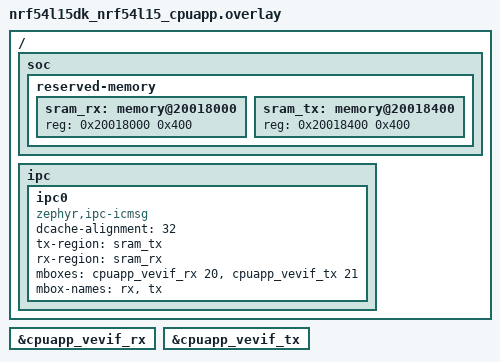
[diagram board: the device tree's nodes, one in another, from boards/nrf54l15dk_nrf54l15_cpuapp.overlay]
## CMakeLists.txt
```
#
# Copyright (c) 2025, Jamie M.
#
# All right reserved. This code is NOT apache or FOSS/copyleft licensed.
#

cmake_minimum_required(VERSION 3.20.0)

find_package(Zephyr REQUIRED HINTS $ENV{ZEPHYR_BASE})
project(test_app_main)

target_sources(app PRIVATE src/main.c src/ipc_endpoint.c src/flipper_cpu.c src/ipc_settings.c src/ipc_crypto.c)

zephyr_include_directories(${ZEPHYR_BINARY_DIR}/include)
generate_inc_file_for_target(
  app
  ${ZEPHYR_BINARY_DIR}/../../remote/zephyr/zephyr.bin
  ${ZEPHYR_BINARY_DIR}/include/generated/remote.inc
  )

zephyr_linker_sources(ROM_START flipper_code.ld)
```

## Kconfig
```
#
# Copyright (c) 2025, Jamie M.
#
# All right reserved. This code is NOT apache or FOSS/copyleft licensed.
#

config IPC_SETTINGS_SERVER
	bool "IPC settings server"
	imply ZMS
	imply ZMS_LOOKUP_CACHE
	imply ZMS_DATA_CRC
	imply ZMS_NO_DOUBLE_WRITE
	select SETTINGS
	imply SETTINGS_RUNTIME
	imply SETTINGS_ZMS_LL_CACHE
	select FLASH
	select FLASH_MAP

config IPC_SETTINGS_CLIENT
	bool "IPC settings client"
	select SETTINGS
	imply SETTINGS_RUNTIME

config IPC_LORAWAN_CRYPTO_SERVER
	bool "IPC LoRaWAN crypto server"

if IPC_SETTINGS_CLIENT

choice SETTINGS_BACKEND
        prompt "Storage back-end"
        default SETTINGS_IPC

config SETTINGS_IPC
        bool "IPC"
        help
          Use IPC as settings storage backend.

endchoice

endif # IPC_SETTINGS_CLIENT

if LORAWAN

choice LORAWAN_NVM
        prompt "LoRaWAN NVM backend"
        default LORAWAN_NVM_IPC_SETTINGS if IPC_SETTINGS_CLIENT

config LORAWAN_NVM_IPC_SETTINGS
        bool "IPC settings based NVM"
        depends on IPC_SETTINGS_CLIENT

endchoice

config IPC_LORAWAN_CRYPTO_CLIENT
	bool "IPC LoRaWAN crypto client"
	select LORAWAN_BELL_IPC_CRYPTO_CLIENT

config LORAWAN_BELL_IPC_CRYPTO_CLIENT
	bool "LoRaWAN IPC secure enclare backend"

endif # LORAWAN

source "Kconfig.zephyr"
```

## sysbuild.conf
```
SB_CONFIG_BOOTLOADER_MCUBOOT=y
SB_CONFIG_APP_USE_COMBINED_HEX_FILE=y
```

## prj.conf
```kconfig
CONFIG_PRINTK=y

CONFIG_LOG=y
CONFIG_LOG_PROCESS_THREAD_PRIORITY=-15
CONFIG_LOG_PROCESS_THREAD_CUSTOM_PRIORITY=y

CONFIG_MAIN_STACK_SIZE=4096
CONFIG_HEAP_MEM_POOL_SIZE=4096

CONFIG_MBOX=y

CONFIG_IPC_SERVICE=y
CONFIG_IPC_SERVICE_LOG_LEVEL_INF=y
CONFIG_IPC_SETTINGS_SERVER=y
CONFIG_IPC_SERVICE_BACKEND_ICMSG_WQ_STACK_SIZE=4096
CONFIG_IPC_LORAWAN_CRYPTO_SERVER=y
CONFIG_PBUF_RX_READ_BUF_SIZE=512
CONFIG_HEAP_MEM_POOL_SIZE=4096

CONFIG_NRF_SECURITY=y

CONFIG_MBEDTLS_PSA_CRYPTO_C=y
CONFIG_MBEDTLS_ENABLE_HEAP=y
CONFIG_MBEDTLS_HEAP_SIZE=8192

CONFIG_PSA_WANT_GENERATE_RANDOM=y
CONFIG_PSA_WANT_KEY_TYPE_AES=y
CONFIG_PSA_WANT_ALG_ECB_NO_PADDING=y
CONFIG_PSA_WANT_ALG_CMAC=y
CONFIG_PSA_CRYPTO_DRIVER_OBERON=n
CONFIG_PSA_CRYPTO_DRIVER_CRACEN=y
```

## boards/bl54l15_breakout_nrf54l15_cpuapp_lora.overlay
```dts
&cpuflpr_vpr {
	status = "okay";
};
```

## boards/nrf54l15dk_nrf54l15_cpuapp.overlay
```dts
/*
 * Copyright (c) 2025 Nordic Semiconductor ASA
 *
 * SPDX-License-Identifier: LicenseRef-Nordic-5-Clause
 */

/ {
	soc {
		reserved-memory {
			#address-cells = <1>;
			#size-cells = <1>;

                        sram_rx: memory@20018000 {
                                reg = <0x20018000 0x400>;
                        };

                        sram_tx: memory@20018400 {
                                reg = <0x20018400 0x400>;
                        };
		};
	};

	ipc {
		ipc0: ipc0 {
			compatible = "zephyr,ipc-icmsg";
			dcache-alignment = <32>;
			tx-region = <&sram_tx>;
			rx-region = <&sram_rx>;
			mboxes = <&cpuapp_vevif_rx 20>, <&cpuapp_vevif_tx 21>;
			mbox-names = "rx", "tx";
			status = "okay";
		};
	};
};

&cpuapp_vevif_rx {
	status = "okay";
};

&cpuapp_vevif_tx {
	status = "okay";
};
```

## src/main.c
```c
/*
 * Copyright (c) 2025, Jamie M.
 *
 * All right reserved. This code is NOT apache or FOSS/copyleft licensed.
 */

#include "ipc_endpoint.h"
#include "ipc_settings.h"
#include <zephyr/kernel.h>
#include <zephyr/settings/settings.h>
#include <zephyr/logging/log.h>

#ifdef CONFIG_IPC_LORAWAN_CRYPTO_SERVER
#include <psa/crypto.h>
#include <psa/crypto_extra.h>
#endif

LOG_MODULE_REGISTER(main, 4);

static uint8_t data[3];

int main(void)
{
	int rc;
	uint8_t up_value = 0;

#ifdef CONFIG_IPC_LORAWAN_CRYPTO_SERVER
	psa_status_t status;
#endif

LOG_ERR("aa1");
	rc = ipc_setup();

	if (rc != 0) {
		return 0;
	}

	rc = settings_subsys_init();

#ifdef CONFIG_IPC_SETTINGS_SERVER
	rc = settings_load();
#endif

LOG_ERR("aa2");
	rc = ipc_wait_for_ready();

	if (rc != 0) {
		return 0;
	}

#ifdef CONFIG_IPC_SETTINGS_SERVER
	ipc_setting_boot_load("lorawan");
#endif

#ifdef CONFIG_IPC_LORAWAN_CRYPTO_SERVER
	status = psa_crypto_init();
	if (status != PSA_SUCCESS) {
		LOG_ERR("Crypto init failed: %d", status);
	}
#endif

LOG_ERR("aa3");
	while (1) {
		k_sleep(K_MSEC(2000));

		data[0] = up_value++;
		data[1] = up_value++;
		data[2] = up_value++;

LOG_HEXDUMP_ERR(data, sizeof(data), "in");

		rc = ipc_send_message(0, sizeof(data), data);

		if (rc < 0) {
			LOG_ERR("Failed to send: %d", rc);
		}
	}

	return 0;
}
```

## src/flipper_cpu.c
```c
/*
 * Copyright (c) 2025, Jamie M.
 *
 * All right reserved. This code is NOT apache or FOSS/copyleft licensed.
 */

#include <zephyr/kernel.h>
#include <zephyr/init.h>
#include <zephyr/devicetree.h>
#include <zephyr/logging/log.h>
#include <hal/nrf_vpr.h>

#define FLPR_SECURE_MODE

#if defined(FLPR_SECURE_MODE) && !defined(CONFIG_TRUSTED_EXECUTION_NONSECURE)
#include <hal/nrf_spu.h>
#endif

static __aligned(0x800) __used __attribute__((section("._flpr_code"))) const uint8_t flpr_firmware[] = {
#include <generated/remote.inc>
};

LOG_MODULE_REGISTER(flpr_cpu, 4);

static int flipper_cpu_launch(void)
{
	NRF_VPR_Type *flpr_cpu = (NRF_VPR_Type *)DT_REG_ADDR(DT_NODELABEL(cpuflpr_vpr));

#if defined(FLPR_SECURE_MODE)
	nrf_spu_periph_perm_secattr_set(NRF_SPU00, nrf_address_slave_get((uint32_t)flpr_cpu),
					true);
#endif

	nrf_vpr_initpc_set(flpr_cpu, (uint32_t)flpr_firmware);
	nrf_vpr_cpurun_set(flpr_cpu, true);

	return 0;
}

SYS_INIT(flipper_cpu_launch, POST_KERNEL, 0);
```

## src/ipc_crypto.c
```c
/*
 * Copyright (c) 2025, Jamie M.
 *
 * All right reserved. This code is NOT apache or FOSS/copyleft licensed.
 */

#include <stdlib.h>
#include <zephyr/types.h>
#include <zephyr/kernel.h>
#include <zephyr/init.h>
#include <zephyr/logging/log.h>
#include "ipc_endpoint.h"
#include "ipc_crypto.h"

#if defined(CONFIG_IPC_LORAWAN_CRYPTO_SERVER)
#elif defined(CONFIG_IPC_LORAWAN_CRYPTO_CLIENT)
#endif

#ifdef CONFIG_IPC_LORAWAN_CRYPTO_SERVER
#include <psa/crypto.h>
#include <psa/crypto_extra.h>
#endif

#define CMAC_AES128_SIZE 16

LOG_MODULE_REGISTER(ipc_crypto, 4);

struct ipc_lorawan_crypto_set_key_data {
	uint8_t type;
	uint16_t key_size;
	uint8_t key[];
};

struct ipc_lorawan_crypto_set_key_response_data {
	int rc;
};

struct ipc_lorawan_crypto_aes128_encrypt_data {
	uint8_t key_id;
	uint16_t data_size;
	uint8_t data[];
};

struct ipc_lorawan_crypto_aes128_encrypt_response_data {
	int rc;
	uint16_t data_size;
	uint8_t data[];
};

struct ipc_lorawan_crypto_cmac_aes128_verify_data {
	uint8_t key_id;
	uint16_t data_size;
	uint16_t signature_size;
	uint8_t data[]; //Data followed by signature
};

struct ipc_lorawan_crypto_cmac_aes128_verify_response_data {
	int rc;
};

/* Client -> server */
static int ipc_lorawan_crypto_callback_set_key(const uint8_t *message, uint16_t size, void *user_data);
static int ipc_lorawan_crypto_callback_aes128_ecb_encrypt(const uint8_t *message, uint16_t size, void *user_data);
static int ipc_lorawan_crypto_callback_aes128_ccm_encrypt(const uint8_t *message, uint16_t size, void *user_data);
static int ipc_lorawan_crypto_callback_cmac_aes128_encrypt(const uint8_t *message, uint16_t size, void *user_data);
static int ipc_lorawan_crypto_callback_cmac_aes128_verify(const uint8_t *message, uint16_t size, void *user_data);

#if defined(CONFIG_IPC_LORAWAN_CRYPTO_CLIENT)
static struct {
	struct k_sem busy;
	struct k_sem done;
	int rc;
	uint8_t *load_pointer;
	uint16_t load_size;
} ipc_lorawan_crypto_data;

static struct ipc_group ipc_group_set_key = {
	.callback = ipc_lorawan_crypto_callback_set_key,
	.opcode = IPC_OPCODE_CRYPTO_SET_KEY,
	.user_data = &ipc_lorawan_crypto_data,
};

static struct ipc_group ipc_group_aes128_ecb_encrypt = {
	.callback = ipc_lorawan_crypto_callback_aes128_ecb_encrypt,
	.opcode = IPC_OPCODE_CRYPTO_AES128_ECB_ENCRYPT,
	.user_data = &ipc_lorawan_crypto_data,
};

static struct ipc_group ipc_group_aes128_ccm_encrypt = {
	.callback = ipc_lorawan_crypto_callback_aes128_ccm_encrypt,
	.opcode = IPC_OPCODE_CRYPTO_AES128_CCM_ENCRYPT,
	.user_data = &ipc_lorawan_crypto_data,
};

static struct ipc_group ipc_group_cmac_aes128_encrypt = {
	.callback = ipc_lorawan_crypto_callback_cmac_aes128_encrypt,
	.opcode = IPC_OPCODE_CRYPTO_CMAC_AES128_ENCRYPT,
	.user_data = &ipc_lorawan_crypto_data,
};

static struct ipc_group ipc_group_cmac_aes128_verify = {
	.callback = ipc_lorawan_crypto_callback_cmac_aes128_verify,
	.opcode = IPC_OPCODE_CRYPTO_CMAC_AES128_VERIFY,
	.user_data = &ipc_lorawan_crypto_data,
};
#endif

#if defined(CONFIG_IPC_LORAWAN_CRYPTO_SERVER)
static struct ipc_group ipc_group_set_key = {
	.callback = ipc_lorawan_crypto_callback_set_key,
	.opcode = IPC_OPCODE_CRYPTO_SET_KEY,
};

static struct ipc_group ipc_group_aes128_ecb_encrypt = {
	.callback = ipc_lorawan_crypto_callback_aes128_ecb_encrypt,
	.opcode = IPC_OPCODE_CRYPTO_AES128_ECB_ENCRYPT,
};

static struct ipc_group ipc_group_aes128_ccm_encrypt = {
	.callback = ipc_lorawan_crypto_callback_aes128_ccm_encrypt,
	.opcode = IPC_OPCODE_CRYPTO_AES128_CCM_ENCRYPT,
};

static struct ipc_group ipc_group_cmac_aes128_encrypt = {
	.callback = ipc_lorawan_crypto_callback_cmac_aes128_encrypt,
	.opcode = IPC_OPCODE_CRYPTO_CMAC_AES128_ENCRYPT,
};

static struct ipc_group ipc_group_cmac_aes128_verify = {
	.callback = ipc_lorawan_crypto_callback_cmac_aes128_verify,
	.opcode = IPC_OPCODE_CRYPTO_CMAC_AES128_VERIFY,
};
#endif

#if defined(CONFIG_IPC_LORAWAN_CRYPTO_SERVER)
static psa_key_id_t magic_key_id;

static int encrypt_aes128(psa_key_id_t *key_id, uint8_t mode, uint8_t *data, uint16_t data_size, uint8_t *encrypted_data)
{
	/* ECB at present */
	uint32_t output_size;
	psa_status_t status;
	psa_cipher_operation_t operation = PSA_CIPHER_OPERATION_INIT;

	status = psa_cipher_encrypt_setup(&operation, *key_id, PSA_ALG_ECB_NO_PADDING);

	if (status != PSA_SUCCESS) {
		LOG_ERR("AES128 ECB setup failed: %d", status);
		return -EINVAL;
	}

	status = psa_cipher_update(&operation, data, data_size, encrypted_data, data_size, &output_size);

	if (status != PSA_SUCCESS) {
		LOG_ERR("AES128 ECB update failed: %d", status);
		return -EINVAL;
	}

	status = psa_cipher_finish(&operation, (encrypted_data + output_size), (data_size - output_size), &output_size);

	if (status != PSA_SUCCESS) {
		LOG_ERR("AES128 ECB finish failed: %d", status);
		return -EINVAL;
	}

LOG_HEXDUMP_ERR(data, data_size, "in");
LOG_HEXDUMP_ERR(encrypted_data, data_size, "out");

	psa_cipher_abort(&operation);

	return 0;
}

static int encrypt_cmac_aes128(psa_key_id_t *key_id, uint8_t *data, uint16_t data_size, uint8_t *cmac, uint16_t cmac_size)
{
	uint32_t output_size;
	psa_status_t status;
	psa_mac_operation_t operation = PSA_MAC_OPERATION_INIT;

	status = psa_mac_sign_setup(&operation, *key_id, PSA_ALG_CMAC);

	if (status != PSA_SUCCESS) {
		LOG_ERR("CMAC AES128 setup failed: %d", status);
		return -EINVAL;
	}

	status = psa_mac_update(&operation, data, data_size);

	if (status != PSA_SUCCESS) {
		LOG_ERR("CMAC AES128 update failed: %d", status);
		return -EINVAL;
	}

	status = psa_mac_sign_finish(&operation, cmac, cmac_size, &output_size);

	if (status != PSA_SUCCESS) {
		LOG_ERR("CMAC AES128 finish failed: %d", status);
		return -EINVAL;
	}

	return 0;
}

static int verify_cmac_aes128(psa_key_id_t *key_id, uint8_t *data, uint16_t data_size, uint8_t *cmac, uint16_t cmac_size)
{
	psa_status_t status;
	psa_mac_operation_t operation = PSA_MAC_OPERATION_INIT;

	status = psa_mac_verify_setup(&operation, *key_id, PSA_ALG_CMAC);

	if (status != PSA_SUCCESS) {
		LOG_ERR("CMAC AES128 setup failed: %d", status);
		return -EINVAL;
	}

	status = psa_mac_update(&operation, data, data_size);

	if (status != PSA_SUCCESS) {
		LOG_ERR("CMAC AES128 update failed: %d", status);
		return -EINVAL;
	}

	status = psa_mac_verify_finish(&operation, cmac, cmac_size);

	if (status != PSA_SUCCESS) {
		LOG_ERR("CMAC AES128 verify failed: %d", status);
		return -EBADMSG;
	}

	return 0;
}

//TODO: this function is temporary and needs removing when KMU is used
static int crypto_cleanup(psa_key_id_t *key_id)
{
	psa_status_t status;

	status = psa_destroy_key(*key_id);

	if (status != PSA_SUCCESS) {
		LOG_ERR("Key removal failed: %d", status);
		return -EINVAL;
	}

	return 0;
}

//TODO: this function is temporary and needs removing when KMU is used
static int ipc_lorawan_crypto_callback_set_key(const uint8_t *message, uint16_t size, void *user_data)
{
	int rc;
	struct ipc_lorawan_crypto_set_key_data *setting = (struct ipc_lorawan_crypto_set_key_data *)message;
	struct ipc_lorawan_crypto_set_key_response_data data;
	psa_status_t status;
	psa_key_attributes_t attributes = PSA_KEY_ATTRIBUTES_INIT;

	if (setting->type == TYPE_AES128) {
		psa_set_key_usage_flags(&attributes, (PSA_KEY_USAGE_ENCRYPT | PSA_KEY_USAGE_DECRYPT));
		psa_set_key_algorithm(&attributes, PSA_ALG_ECB_NO_PADDING);
	} else if (setting->type == TYPE_CMAC_AES128) {
		psa_set_key_usage_flags(&attributes, (PSA_KEY_USAGE_VERIFY_HASH | PSA_KEY_USAGE_SIGN_HASH));
		psa_set_key_algorithm(&attributes, PSA_ALG_CMAC);
	}

//LOG_HEXDUMP_ERR(setting->key, setting->key_size, "key");
//LOG_HEXDUMP_ERR(message, size, "key");

	psa_set_key_lifetime(&attributes, PSA_KEY_LIFETIME_VOLATILE);
	psa_set_key_type(&attributes, PSA_KEY_TYPE_AES);
	psa_set_key_bits(&attributes, 128);
	status = psa_import_key(&attributes, setting->key, setting->key_size, &magic_key_id);

	if (status != PSA_SUCCESS) {
		LOG_ERR("Key import failed: %d", status);
		data.rc = -EINVAL;
	} else {
		data.rc = 0;
	}

	rc = ipc_send_message(IPC_OPCODE_CRYPTO_SET_KEY, sizeof(data), (uint8_t *)&data);

	return rc;
}

static int ipc_lorawan_crypto_callback_aes128_ecb_encrypt(const uint8_t *message, uint16_t size, void *user_data)
{
	int rc;
	int rc_cleanup;
	struct ipc_lorawan_crypto_aes128_encrypt_data *setting = (struct ipc_lorawan_crypto_aes128_encrypt_data *)message;
	struct ipc_lorawan_crypto_aes128_encrypt_response_data *data;
	uint16_t total_size = sizeof(struct ipc_lorawan_crypto_aes128_encrypt_response_data) + setting->data_size;

	data = (struct ipc_lorawan_crypto_aes128_encrypt_response_data *)malloc(total_size);

	rc = encrypt_aes128(&magic_key_id, 0, setting->data, setting->data_size, data->data);
	data->rc = rc;
LOG_ERR("encrypt: %d", rc);

	if (rc == 0) {
		data->data_size = setting->data_size;
	}

	rc_cleanup = crypto_cleanup(&magic_key_id);
LOG_ERR("finish: %d", rc_cleanup);

	rc = ipc_send_message(IPC_OPCODE_CRYPTO_AES128_ECB_ENCRYPT, total_size, (uint8_t *)data);
	free(data);

	return rc;
}

static int ipc_lorawan_crypto_callback_aes128_ccm_encrypt(const uint8_t *message, uint16_t size, void *user_data)
{
	int rc;
	struct ipc_lorawan_crypto_aes128_encrypt_data *setting = (struct ipc_lorawan_crypto_aes128_encrypt_data *)message;
	struct ipc_lorawan_crypto_aes128_encrypt_response_data data;

LOG_ERR("abc1: %d", rc);
data.rc = rc;

	rc = ipc_send_message(IPC_OPCODE_CRYPTO_AES128_CCM_ENCRYPT, sizeof(data), (uint8_t *)&data);

	return rc;
}

static int ipc_lorawan_crypto_callback_cmac_aes128_encrypt(const uint8_t *message, uint16_t size, void *user_data)
{
	int rc;
	int rc_cleanup;
	struct ipc_lorawan_crypto_aes128_encrypt_data *setting = (struct ipc_lorawan_crypto_aes128_encrypt_data *)message;
	struct ipc_lorawan_crypto_aes128_encrypt_response_data *data;
	uint16_t total_size = sizeof(struct ipc_lorawan_crypto_aes128_encrypt_response_data) + CMAC_AES128_SIZE;

	data = (struct ipc_lorawan_crypto_aes128_encrypt_response_data *)malloc(total_size);

	rc = encrypt_cmac_aes128(&magic_key_id, setting->data, setting->data_size, data->data, CMAC_AES128_SIZE);
	data->rc = rc;

	if (rc == 0) {
		data->data_size = CMAC_AES128_SIZE;
	}

	rc_cleanup = crypto_cleanup(&magic_key_id);
LOG_ERR("finish: %d", rc_cleanup);

	rc = ipc_send_message(IPC_OPCODE_CRYPTO_CMAC_AES128_ENCRYPT, total_size, (uint8_t *)data);

	return rc;
}

static int ipc_lorawan_crypto_callback_cmac_aes128_verify(const uint8_t *message, uint16_t size, void *user_data)
{
	int rc;
	int rc_cleanup;
	struct ipc_lorawan_crypto_cmac_aes128_verify_data *setting = (struct ipc_lorawan_crypto_cmac_aes128_verify_data *)message;
	struct ipc_lorawan_crypto_cmac_aes128_verify_response_data data;

	rc = verify_cmac_aes128(&magic_key_id, setting->data, setting->data_size, &setting->data[setting->data_size], setting->signature_size);
	data.rc = rc;
LOG_ERR("cmac verify: %d", rc);

	rc_cleanup = crypto_cleanup(&magic_key_id);
LOG_ERR("finish: %d", rc_cleanup);

	rc = ipc_send_message(IPC_OPCODE_CRYPTO_CMAC_AES128_VERIFY, sizeof(data), (uint8_t *)&data);

	return rc;
}
#endif

#if defined(CONFIG_IPC_LORAWAN_CRYPTO_CLIENT)
static int ipc_lorawan_crypto_callback_set_key(const uint8_t *message, uint16_t size, void *user_data)
{
//get error, give sem
	struct ipc_lorawan_crypto_set_key_response_data *data = (struct ipc_lorawan_crypto_set_key_response_data *)message;

	ipc_lorawan_crypto_data.rc = data->rc;
LOG_ERR("abc4: %d", data->rc);

	k_sem_give(&ipc_lorawan_crypto_data.done);

	return 0;
}

static int ipc_lorawan_crypto_callback_aes128_ecb_encrypt(const uint8_t *message, uint16_t size, void *user_data)
{
//get error, give sem
	struct ipc_lorawan_crypto_aes128_encrypt_response_data *data = (struct ipc_lorawan_crypto_aes128_encrypt_response_data *)message;

//check length/null
LOG_ERR("rc1? %d, len? %d, ", data->rc, data->data_size);
//LOG_HEXDUMP_ERR(data->data, data->data_size, "tmp");
	if (data->rc == 0) {
//LOG_ERR("move to %p", ipc_lorawan_crypto_data.load_pointer);
		memcpy(ipc_lorawan_crypto_data.load_pointer, data->data, data->data_size);
	}

	ipc_lorawan_crypto_data.load_pointer = NULL;
	ipc_lorawan_crypto_data.load_size = data->data_size;
	ipc_lorawan_crypto_data.rc = data->rc;
//LOG_ERR("abc5: %d", data->rc);

	k_sem_give(&ipc_lorawan_crypto_data.done);

	return 0;
}

static int ipc_lorawan_crypto_callback_aes128_ccm_encrypt(const uint8_t *message, uint16_t size, void *user_data)
{
//get error, give sem
	struct ipc_lorawan_crypto_aes128_encrypt_response_data *data = (struct ipc_lorawan_crypto_aes128_encrypt_response_data *)message;

	ipc_lorawan_crypto_data.rc = data->rc;
//LOG_ERR("abc6: %d", data->rc);

	k_sem_give(&ipc_lorawan_crypto_data.done);

	return 0;
}

static int ipc_lorawan_crypto_callback_cmac_aes128_encrypt(const uint8_t *message, uint16_t size, void *user_data)
{
//get error, give sem
	struct ipc_lorawan_crypto_aes128_encrypt_response_data *data = (struct ipc_lorawan_crypto_aes128_encrypt_response_data *)message;

//check length/null
LOG_ERR("rc2? %d, len? %d, ", data->rc, data->data_size);
//LOG_HEXDUMP_ERR(data->data, data->data_size, "tmp");
	if (data->rc == 0) {
		memcpy(ipc_lorawan_crypto_data.load_pointer, data->data, data->data_size);
	}

	ipc_lorawan_crypto_data.load_pointer = NULL;
	ipc_lorawan_crypto_data.load_size = data->data_size;
	ipc_lorawan_crypto_data.rc = data->rc;
//LOG_ERR("abc5: %d", data->rc);

	k_sem_give(&ipc_lorawan_crypto_data.done);

	return 0;
}

static int ipc_lorawan_crypto_callback_cmac_aes128_verify(const uint8_t *message, uint16_t size, void *user_data)
{
//get error, give sem
	struct ipc_lorawan_crypto_cmac_aes128_verify_response_data *data = (struct ipc_lorawan_crypto_cmac_aes128_verify_response_data *)message;

	ipc_lorawan_crypto_data.rc = data->rc;
LOG_ERR("abc8: %d", data->rc);

	k_sem_give(&ipc_lorawan_crypto_data.done);

	return 0;
}

int ipc_lorawan_crypto_set_key(uint8_t *key, uint16_t key_size, uint8_t usage)
{
	int rc;
	struct ipc_lorawan_crypto_set_key_data *data;
	uint16_t total_size = sizeof(struct ipc_lorawan_crypto_set_key_data) + key_size;

	rc = k_sem_take(&ipc_lorawan_crypto_data.busy, K_FOREVER);

	data = (struct ipc_lorawan_crypto_set_key_data *)malloc(total_size);
	data->type = usage;
	data->key_size = key_size;
	memcpy(data->key, key, key_size);

	rc = ipc_send_message(IPC_OPCODE_CRYPTO_SET_KEY, total_size, (uint8_t *)data);
	free(data);

//check length?
	if (rc < 0) {
		goto finish;
	}

	rc = k_sem_take(&ipc_lorawan_crypto_data.done, K_FOREVER);

	if (rc == 0) {
		rc = ipc_lorawan_crypto_data.rc;
	}

finish:
	k_sem_give(&ipc_lorawan_crypto_data.busy);
	return rc;
}

int ipc_lorawan_crypto_aes128_ecb_encrypt(uint8_t key_id, uint8_t *data, uint16_t data_size, uint8_t *encrypted_data)
{
	int rc;
	struct ipc_lorawan_crypto_aes128_encrypt_data *internal_data;
	uint16_t total_size = sizeof(struct ipc_lorawan_crypto_aes128_encrypt_data) + data_size;

	rc = k_sem_take(&ipc_lorawan_crypto_data.busy, K_FOREVER);

	internal_data = (struct ipc_lorawan_crypto_aes128_encrypt_data *)malloc(total_size);
	internal_data->key_id = key_id;
	internal_data->data_size = data_size;
	memcpy(internal_data->data, data, data_size);

	ipc_lorawan_crypto_data.load_pointer = encrypted_data;
	ipc_lorawan_crypto_data.load_size = data_size;

	rc = ipc_send_message(IPC_OPCODE_CRYPTO_AES128_ECB_ENCRYPT, total_size, (uint8_t *)internal_data);
	free(internal_data);

//check length?
	if (rc < 0) {
		goto finish;
	}

	rc = k_sem_take(&ipc_lorawan_crypto_data.done, K_FOREVER);

	if (rc == 0) {
		rc = ipc_lorawan_crypto_data.rc;
	}

//LOG_HEXDUMP_ERR(data, data_size, "in");
//LOG_HEXDUMP_ERR(encrypted_data, data_size, "out");

finish:
	k_sem_give(&ipc_lorawan_crypto_data.busy);
	return rc;
}

int ipc_lorawan_crypto_cmac_aes128_encrypt(uint8_t key_id, uint8_t *data, uint16_t data_size, uint8_t *prior_data, uint16_t prior_data_size, uint8_t *encrypted_data)
{
	int rc;
	struct ipc_lorawan_crypto_aes128_encrypt_data *internal_data;
	uint16_t total_size = sizeof(struct ipc_lorawan_crypto_aes128_encrypt_data) + data_size + prior_data_size;

	rc = k_sem_take(&ipc_lorawan_crypto_data.busy, K_FOREVER);

	internal_data = (struct ipc_lorawan_crypto_aes128_encrypt_data *)malloc(total_size);
	internal_data->key_id = key_id;
	internal_data->data_size = data_size + prior_data_size;

	if (prior_data_size > 0) {
		memcpy(internal_data->data, prior_data, prior_data_size);
	}

	memcpy(&internal_data->data[prior_data_size], data, data_size);

	ipc_lorawan_crypto_data.load_pointer = encrypted_data;
	ipc_lorawan_crypto_data.load_size = data_size;

	rc = ipc_send_message(IPC_OPCODE_CRYPTO_CMAC_AES128_ENCRYPT, total_size, (uint8_t *)internal_data);
	free(internal_data);

//check length?
	if (rc < 0) {
		goto finish;
	}

	rc = k_sem_take(&ipc_lorawan_crypto_data.done, K_FOREVER);

	if (rc == 0) {
		rc = ipc_lorawan_crypto_data.rc;
	}

//LOG_HEXDUMP_ERR(data, data_size, "in");
//LOG_HEXDUMP_ERR(encrypted_data, data_size, "out");

finish:
	k_sem_give(&ipc_lorawan_crypto_data.busy);
	return rc;
}
#endif

static int ipc_lorawan_crypto_register(void)
{
#if defined(CONFIG_IPC_LORAWAN_CRYPTO_CLIENT)
	k_sem_init(&ipc_lorawan_crypto_data.busy, 1, 1);
	k_sem_init(&ipc_lorawan_crypto_data.done, 0, 1);
	ipc_lorawan_crypto_data.load_pointer = NULL;
	ipc_lorawan_crypto_data.load_size = 0;
#endif

	ipc_register(&ipc_group_set_key);
	ipc_register(&ipc_group_aes128_ecb_encrypt);
	ipc_register(&ipc_group_aes128_ccm_encrypt);
	ipc_register(&ipc_group_cmac_aes128_encrypt);
	ipc_register(&ipc_group_cmac_aes128_verify);

	return 0;
}

SYS_INIT(ipc_lorawan_crypto_register, APPLICATION, 0);
```

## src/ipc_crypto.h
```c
/*
 * Copyright (c) 2025, Jamie M.
 *
 * All right reserved. This code is NOT apache or FOSS/copyleft licensed.
 */

#include <stdint.h>

enum usage_type {
	TYPE_AES128,
	TYPE_CMAC_AES128,
};

int ipc_lorawan_crypto_set_key(uint8_t *key, uint16_t key_size, uint8_t usage);
int ipc_lorawan_crypto_aes128_ecb_encrypt(uint8_t key_id, uint8_t *data, uint16_t data_size, uint8_t *encrypted_data);
int ipc_lorawan_crypto_cmac_aes128_encrypt(uint8_t key_id, uint8_t *data, uint16_t data_size, uint8_t *prior_data, uint16_t prior_data_size, uint8_t *encrypted_data);
```

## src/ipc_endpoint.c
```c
/*
 * Copyright (c) 2025, Jamie M.
 *
 * All right reserved. This code is NOT apache or FOSS/copyleft licensed.
 */

#include <string.h>
#include <zephyr/kernel.h>
#include <zephyr/device.h>
#include <zephyr/ipc/ipc_service.h>
#include <zephyr/logging/log.h>
#include "ipc_endpoint.h"

LOG_MODULE_REGISTER(ipc_endpoint, 4);

#define IPC_MESSAGE_OVERHEAD (data_payload.data - &data_payload.opcode)
#define IPC_MESSAGE_DATA_SIZE 512

struct ipc_payload {
	uint8_t opcode;
	uint16_t size;
	uint8_t data[IPC_MESSAGE_DATA_SIZE];
};

static void ipc_endpoint_bound(void *priv);
static void ipc_endpoint_receive(const void *data, size_t len, void *priv);

static sys_slist_t ipc_registered_handlers = SYS_SLIST_STATIC_INIT(&ipc_registered_handlers);
static struct ipc_payload data_payload;
static struct ipc_ept ipc_endpoint;
static K_SEM_DEFINE(ipc_bound_sem, 0, 1);
static K_SEM_DEFINE(ipc_receive_sem, 0, 1);

static struct ipc_ept_cfg ipc_endpoint_config = {
	.name = "ep0",
	.cb = {
		.bound = ipc_endpoint_bound,
		.received = ipc_endpoint_receive,
	},
};

static void ipc_endpoint_bound(void *priv)
{
	k_sem_give(&ipc_bound_sem);
}

static void ipc_endpoint_receive(const void *data, size_t len, void *priv)
{
	sys_snode_t *snp, *sns;
	struct ipc_payload *values = (struct ipc_payload *)data;

	if (len > sizeof(struct ipc_payload)) {
		printk("invalid len: %d", len);
	} else if (len != (values->size + IPC_MESSAGE_OVERHEAD)) {
		printk("len mismatch: %d vs %d", len, (values->size + IPC_MESSAGE_OVERHEAD));
	} else {
		printk("got message! %d, %d, %d, %d, %d\n", values->opcode, values->size, values->data[0], values->data[1], values->data[2]);
LOG_HEXDUMP_ERR(data, len, "DAT");
	}

	SYS_SLIST_FOR_EACH_NODE_SAFE(&ipc_registered_handlers, snp, sns) {
		struct ipc_group *group = CONTAINER_OF(snp, struct ipc_group, node);

		if (group->opcode == values->opcode) {
			(void)group->callback(&values->data[0], values->size, group->user_data);
			break;
		}
	}

	k_sem_give(&ipc_receive_sem);
}

int ipc_setup(void)
{
	int rc;
	const struct device *ipc_device = DEVICE_DT_GET(DT_NODELABEL(ipc0));

	rc = ipc_service_open_instance(ipc_device);

	if (rc < 0 && rc != -EALREADY) {
		LOG_ERR("IPC service open fail: %d", rc);
		return rc;
	}

	rc = ipc_service_register_endpoint(ipc_device, &ipc_endpoint, &ipc_endpoint_config);

	if (rc < 0) {
		LOG_ERR("IPC service register fail: %d", rc);
		return rc;
	}

	return 0;
}

int ipc_wait_for_ready()
{
	k_sem_take(&ipc_bound_sem, K_FOREVER);
	return 0;
}

int ipc_send_message(uint8_t opcode, uint16_t size, const uint8_t *message)
{
	int rc;

	if (size > sizeof(struct ipc_payload)) {
		return -1;
	}

	data_payload.opcode = opcode;
	data_payload.size = size;
//LOG_HEXDUMP_ERR(message, size, "out");
	memcpy(data_payload.data, message, size);
//LOG_HEXDUMP_ERR(&data_payload, (size + IPC_MESSAGE_OVERHEAD), "out2");

	rc = ipc_service_send(&ipc_endpoint, &data_payload, (size + IPC_MESSAGE_OVERHEAD));

	return rc;
}

void ipc_register(struct ipc_group *group)
{
	sys_slist_append(&ipc_registered_handlers, &group->node);
}

void ipc_unregister(struct ipc_group *group)
{
	(void)sys_slist_find_and_remove(&ipc_registered_handlers, &group->node);
}
```

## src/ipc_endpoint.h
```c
/*
 * Copyright (c) 2025, Jamie M.
 *
 * All right reserved. This code is NOT apache or FOSS/copyleft licensed.
 */

#ifndef APP_IPC_ENDPOINT_H
#define APP_IPC_ENDPOINT_H

#include <stdint.h>
#include <zephyr/sys/slist.h>

enum ipc_opcode {
	/* Settings */
	/* | Client -> server */
	IPC_OPCODE_SETTINGS_SAVE,
	IPC_OPCODE_SETTINGS_LOAD,
	IPC_OPCODE_SETTINGS_COMMIT,
	IPC_OPCODE_SETTINGS_TREE_COUNT,
	IPC_OPCODE_SETTINGS_TREE_LOAD,

	/* | Server -> client */
	IPC_OPCODE_SETTINGS_BOOT_LOAD,

	/* Crypto */
	/* | Client -> server */
	IPC_OPCODE_CRYPTO_SET_KEY,
	IPC_OPCODE_CRYPTO_AES128_ECB_ENCRYPT,
	IPC_OPCODE_CRYPTO_AES128_CCM_ENCRYPT,
	IPC_OPCODE_CRYPTO_CMAC_AES128_ENCRYPT,
	IPC_OPCODE_CRYPTO_CMAC_AES128_VERIFY,
};

typedef int (*ipc_callback_fn)(const uint8_t *message, uint16_t size, void *user_data);

struct ipc_group {
	sys_snode_t node;
	ipc_callback_fn callback;
	uint8_t opcode;
	void *user_data;
};

/*
save: name, value, size
load: name -> value, size
*/

/** Setup IPC service */
int ipc_setup(void);

/** Wait for IPC service on remote end to be ready */
int ipc_wait_for_ready();

/** Send message over IPC */
int ipc_send_message(uint8_t opcode, uint16_t size, const uint8_t *message);

/** Register IPC callback handler for an opcode */
void ipc_register(struct ipc_group *group);

/** Unregister IPC callback handler for an opcode */
void ipc_unregister(struct ipc_group *group);

#endif /* APP_IPC_ENDPOINT_H */
```

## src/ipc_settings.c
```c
/*
 * Copyright (c) 2025, Jamie M.
 *
 * All right reserved. This code is NOT apache or FOSS/copyleft licensed.
 */

#include <stdlib.h>
#include <zephyr/types.h>
#include <zephyr/kernel.h>
#include <zephyr/init.h>
#include <zephyr/settings/settings.h>
#include <zephyr/logging/log.h>
#include "ipc_endpoint.h"

#if defined(CONFIG_IPC_SETTINGS_SERVER)
#include <zephyr/settings/settings.h>
#endif

LOG_MODULE_REGISTER(ipc_settings, 4);

struct ipc_setting_save_data {
	uint8_t name_size;
	uint8_t value_size;
	uint8_t setting[]; //Name, followed by value
};

struct ipc_setting_save_response_data {
	int rc;
};

struct ipc_setting_load_data {
	uint8_t name_size;
	uint8_t max_value_size;
	uint8_t name[];
};

struct ipc_setting_load_response_data {
	int rc;
	uint8_t value_size;
	uint8_t setting[];
};

struct ipc_setting_commit_response_data {
	int rc;
};

#if 0
struct ipc_setting_tree_count_response_data {
	uint16_t count;
};

struct ipc_setting_tree_load_data {
	uint16_t index;
};

struct ipc_setting_tree_load_response_data {
	int rc;
	uint8_t *name;
	uint8_t *value;
	uint8_t *value_size;
};
#endif

struct ipc_setting_boot_load_data {
	uint8_t name_size;
	uint8_t value_size;
	uint8_t setting[]; //Name, followed by value
};

/* Client -> server */
static int ipc_setting_callback_save(const uint8_t *message, uint16_t size, void *user_data);
static int ipc_setting_callback_load(const uint8_t *message, uint16_t size, void *user_data);
static int ipc_setting_callback_commit(const uint8_t *message, uint16_t size, void *user_data);
#if 0
static int ipc_setting_callback_tree_count(const uint8_t *message, uint16_t size, void *user_data);
static int ipc_setting_callback_tree_load(const uint8_t *message, uint16_t size, void *user_data);
#endif

/* Server -> client */
static int ipc_setting_callback_boot_load(const uint8_t *message, uint16_t size, void *user_data);

#if defined(CONFIG_IPC_SETTINGS_CLIENT)
static struct {
	struct k_sem busy;
	struct k_sem done;
	int rc;
	uint8_t *load_pointer;
	uint8_t load_size;
} ipc_settings_data;

static struct ipc_group ipc_group_save = {
	.callback = ipc_setting_callback_save,
	.opcode = IPC_OPCODE_SETTINGS_SAVE,
	.user_data = &ipc_settings_data,
};

static struct ipc_group ipc_group_load = {
	.callback = ipc_setting_callback_load,
	.opcode = IPC_OPCODE_SETTINGS_LOAD,
	.user_data = &ipc_settings_data,
};

static struct ipc_group ipc_group_commit = {
	.callback = ipc_setting_callback_commit,
	.opcode = IPC_OPCODE_SETTINGS_COMMIT,
	.user_data = &ipc_settings_data,
};

#if 0
static struct ipc_group ipc_group_tree_count = {
	.callback = ipc_setting_callback_tree_count,
	.opcode = IPC_OPCODE_SETTINGS_TREE_COUNT,
	.user_data = &ipc_settings_data,
};

static struct ipc_group ipc_group_tree_load = {
	.callback = ipc_setting_callback_tree_load,
	.opcode = IPC_OPCODE_SETTINGS_TREE_LOAD,
	.user_data = &ipc_settings_data,
};
#endif

static struct ipc_group ipc_group_boot_load = {
	.callback = ipc_setting_callback_boot_load,
	.opcode = IPC_OPCODE_SETTINGS_BOOT_LOAD,
};
#endif

#if defined(CONFIG_IPC_SETTINGS_SERVER)
static struct {
	struct k_sem busy;
	struct k_sem done;
	int rc;
} ipc_settings_data;

static struct ipc_group ipc_group_save = {
	.callback = ipc_setting_callback_save,
	.opcode = IPC_OPCODE_SETTINGS_SAVE,
};

static struct ipc_group ipc_group_load = {
	.callback = ipc_setting_callback_load,
	.opcode = IPC_OPCODE_SETTINGS_LOAD,
};

static struct ipc_group ipc_group_commit = {
	.callback = ipc_setting_callback_commit,
	.opcode = IPC_OPCODE_SETTINGS_COMMIT,
};

#if 0
static struct ipc_group ipc_group_tree_count = {
	.callback = ipc_setting_callback_tree_count,
	.opcode = IPC_OPCODE_SETTINGS_TREE_COUNT,
};

static struct ipc_group ipc_group_tree_load = {
	.callback = ipc_setting_callback_tree_load,
	.opcode = IPC_OPCODE_SETTINGS_TREE_LOAD,
};
#endif

static struct ipc_group ipc_group_boot_load = {
	.callback = ipc_setting_callback_boot_load,
	.opcode = IPC_OPCODE_SETTINGS_BOOT_LOAD,
	.user_data = &ipc_settings_data,
};
#endif

#if defined(CONFIG_IPC_SETTINGS_SERVER)
static int ipc_setting_callback_save(const uint8_t *message, uint16_t size, void *user_data)
{
	int rc;
	struct ipc_setting_save_data *setting = (struct ipc_setting_save_data *)message;
	struct ipc_setting_save_response_data data;

	rc = settings_save_one(setting->setting, &setting->setting[setting->name_size], setting->value_size);

LOG_ERR("abc: %d for %s", rc, setting->setting);
data.rc = rc;

	rc = ipc_send_message(IPC_OPCODE_SETTINGS_SAVE, sizeof(data), (uint8_t *)&data);

	return rc;
}

static int ipc_setting_callback_load(const uint8_t *message, uint16_t size, void *user_data)
{
	int rc;
	struct ipc_setting_load_data *setting = (struct ipc_setting_load_data *)message;
	struct ipc_setting_load_response_data *data;

	data = (struct ipc_setting_load_response_data *)malloc(16);

	rc = settings_runtime_get(setting->name, data->setting, setting->max_value_size);

LOG_ERR("def: %d for %s", rc, setting->name);
data->rc = rc;

	data->value_size = (rc >= 0 ? rc : 0);

	rc = ipc_send_message(IPC_OPCODE_SETTINGS_LOAD, 16, (uint8_t *)data);
	free(data);

	return rc;
}

static int ipc_setting_callback_commit(const uint8_t *message, uint16_t size, void *user_data)
{
	int rc;
	struct ipc_setting_commit_response_data data;

	rc = settings_save();
data.rc = rc;

	rc = ipc_send_message(IPC_OPCODE_SETTINGS_COMMIT, sizeof(data), (uint8_t *)&data);

	return rc;
}

#if 0
static int setting_count_callback(const char *key, size_t len, settings_read_cb read_cb, void *cb_arg, void *param)
{
	uint16_t *entries = (uint16_t *)param;

	++*entries;
}

static int ipc_setting_callback_tree_count(const uint8_t *message, uint16_t size, void *user_data)
{
	int rc;
	uint16_t entries = 0;
	struct ipc_setting_tree_count_response_data data;

	rc = settings_load_subtree_direct(NULL, setting_count_callback, &entries);

	if (rc < 0) {
		return rc;
	}

LOG_ERR("stgs: %d", entries);

	data.count = entries;
	rc = ipc_send_message(IPC_OPCODE_SETTINGS_TREE_COUNT, sizeof(data), (uint8_t *)&data);

	return rc;
}

static int ipc_setting_callback_tree_load(const uint8_t *message, uint16_t size, void *user_data)
{
	int rc;
	struct ipc_setting_tree_load_data *setting = (struct ipc_setting_tree_load_data *)message;
	struct ipc_setting_tree_load_response_data *data;

#if 0
	rc = settings_runtime_get(setting->name, data->setting, setting->max_value_size);

LOG_ERR("def: %d for %s", rc, setting->name);
data->rc = rc;
#endif

	data->value_size = (rc >= 0 ? rc : 0);

	rc = ipc_send_message(IPC_OPCODE_SETTINGS_TREE_LOAD, 16, (uint8_t *)data);
	free(data);

	return rc;
}
#endif

static int ipc_setting_callback_boot_load(const uint8_t *message, uint16_t size, void *user_data)
{
	k_sem_give(&ipc_settings_data.done);
	return 0;
}

static int ipc_setting_boot_load_loop(const char *name, size_t value_size, settings_read_cb read_cb, void *cb_arg, void *param)
{
	int rc;
	struct ipc_setting_boot_load_data *data;
	uint8_t *key = (uint8_t *)param;
	uint8_t key_size = strlen(key) + 1;
	uint8_t part_size = strlen(name) + 1;
	uint8_t name_size = key_size + part_size;
	uint16_t total_size = sizeof(struct ipc_setting_boot_load_data) + name_size + value_size;

	data = (struct ipc_setting_boot_load_data *)malloc(total_size);

	data->name_size = name_size;
	data->value_size = value_size;
	memcpy(data->setting, key, key_size);
	data->setting[(key_size - 1)] = '/';
	memcpy(&data->setting[key_size], name, part_size);
	(void)read_cb(cb_arg, &data->setting[name_size], value_size);

LOG_ERR("setting: %s length: %d", name, value_size);

	rc = ipc_send_message(IPC_OPCODE_SETTINGS_BOOT_LOAD, total_size, (uint8_t *)data);
	free(data);

//check length?
	if (rc < 0) {
		goto finish;
	}

	rc = k_sem_take(&ipc_settings_data.done, K_FOREVER);

finish:
	return rc;
}

int ipc_setting_boot_load(uint8_t *key)
{
	int rc;

	rc = k_sem_take(&ipc_settings_data.busy, K_FOREVER);
	rc = settings_load_subtree_direct(key, ipc_setting_boot_load_loop, key);
	k_sem_give(&ipc_settings_data.busy);
	return rc;
}

#endif

#if defined(CONFIG_IPC_SETTINGS_CLIENT)
static int ipc_setting_callback_save(const uint8_t *message, uint16_t size, void *user_data)
{
//get error, give sem
	struct ipc_setting_save_response_data *data = (struct ipc_setting_save_response_data *)message;

	ipc_settings_data.rc = data->rc;
LOG_ERR("abc: %d", data->rc);

	k_sem_give(&ipc_settings_data.done);

	return 0;
}

static int ipc_setting_callback_load(const uint8_t *message, uint16_t size, void *user_data)
{
	struct ipc_setting_load_response_data *data = (struct ipc_setting_load_response_data *)message;
	ipc_settings_data.rc = data->rc;

//do null check on ipc_settings_data.load_pointer ? do size check on ipc_settings_data.load_size ?

LOG_HEXDUMP_ERR(data->setting, data->rc, "teh");

	memcpy(ipc_settings_data.load_pointer, data->setting, data->value_size);

	ipc_settings_data.load_pointer = NULL;
	ipc_settings_data.load_size = 0;
LOG_ERR("def: %d", data->rc);

	k_sem_give(&ipc_settings_data.done);

	return 0;
}

static int ipc_setting_callback_commit(const uint8_t *message, uint16_t size, void *user_data)
{
	struct ipc_setting_commit_response_data *data = (struct ipc_setting_commit_response_data *)message;

	ipc_settings_data.rc = data->rc;
LOG_ERR("qui: %d", data->rc);

	k_sem_give(&ipc_settings_data.done);

	return 0;
}

#if 0
static int ipc_setting_callback_tree_count(const uint8_t *message, uint16_t size, void *user_data)
{
	struct ipc_setting_tree_count_response_data *data = (struct ipc_setting_tree_count_response_data *)message;

	ipc_settings_data.rc = data->count;
LOG_ERR("qui: %d", data->count);

	k_sem_give(&ipc_settings_data.done);

	return 0;
}

static int ipc_setting_callback_tree_load(const uint8_t *message, uint16_t size, void *user_data)
{
}
#endif

static int ipc_setting_callback_boot_load_read_value(void *cb_arg, void *data, size_t len)
{
	struct ipc_setting_boot_load_data *setting = (struct ipc_setting_boot_load_data *)cb_arg;

	if (len > setting->value_size) {
		len = setting->value_size;
	}

	memcpy(data, &setting->setting[setting->name_size], len);

	return len;
}

static int ipc_setting_callback_boot_load(const uint8_t *message, uint16_t size, void *user_data)
{
	int rc;
	struct ipc_setting_boot_load_data *setting = (struct ipc_setting_boot_load_data *)message;

LOG_ERR("got %d length value for %s", setting->value_size, setting->setting);

	rc = settings_call_set_handler(setting->setting, setting->value_size,
				       &ipc_setting_callback_boot_load_read_value, setting, NULL);

	rc = ipc_send_message(IPC_OPCODE_SETTINGS_BOOT_LOAD, 0, NULL);

	return rc;
}

int ipc_setting_save(uint8_t *name, uint8_t *value, uint8_t value_size)
{
	int rc;
	struct ipc_setting_save_data *data;
	uint8_t name_size = strlen(name) + 1;
	uint16_t total_size = sizeof(struct ipc_setting_save_data) + name_size + value_size;

	rc = k_sem_take(&ipc_settings_data.busy, K_FOREVER);

	data = (struct ipc_setting_save_data *)malloc(total_size);
	data->name_size = name_size;
	data->value_size = value_size;
	memcpy(data->setting, name, name_size);
	memcpy((data->setting + name_size), value, value_size);

	rc = ipc_send_message(IPC_OPCODE_SETTINGS_SAVE, total_size, (uint8_t *)data);
	free(data);

//check length?
	if (rc < 0) {
		goto finish;
	}

	rc = k_sem_take(&ipc_settings_data.done, K_FOREVER);

	if (rc == 0) {
		rc = ipc_settings_data.rc;
	}

finish:
	k_sem_give(&ipc_settings_data.busy);
	return rc;
}

int ipc_setting_load(uint8_t *name, uint8_t *value, uint8_t max_value_size)
{
	int rc;
	struct ipc_setting_load_data *data;
	uint8_t name_size = strlen(name) + 1;
	uint16_t total_size = sizeof(struct ipc_setting_load_data) + name_size;

	rc = k_sem_take(&ipc_settings_data.busy, K_FOREVER);

	data = (struct ipc_setting_load_data *)malloc(total_size);
	data->name_size = name_size;
	data->max_value_size = max_value_size;
	memcpy(data->name, name, name_size);
	ipc_settings_data.load_pointer = value;
	ipc_settings_data.load_size = max_value_size;

	rc = ipc_send_message(IPC_OPCODE_SETTINGS_LOAD, total_size, (uint8_t *)data);
	free(data);

//check length?
	if (rc < 0) {
		goto finish;
	}

	rc = k_sem_take(&ipc_settings_data.done, K_FOREVER);

	if (rc == 0) {
		rc = ipc_settings_data.rc;
	}

finish:
	k_sem_give(&ipc_settings_data.busy);
	return rc;
}

int ipc_setting_commit()
{
	int rc;

	rc = k_sem_take(&ipc_settings_data.busy, K_FOREVER);
	rc = ipc_send_message(IPC_OPCODE_SETTINGS_COMMIT, 0, NULL);

//check length?
	if (rc < 0) {
		goto finish;
	}

	rc = k_sem_take(&ipc_settings_data.done, K_FOREVER);

	if (rc == 0) {
		rc = ipc_settings_data.rc;
	}

finish:
	k_sem_give(&ipc_settings_data.busy);
	return rc;
}

#if 0
int ipc_setting_tree_count(uint16_t *count)
{
	int rc;

	rc = k_sem_take(&ipc_settings_data.busy, K_FOREVER);
	rc = ipc_send_message(IPC_OPCODE_SETTINGS_TREE_COUNT, 0, NULL);

//check length?
LOG_ERR("uu1 %d", rc);
	if (rc < 0) {
		goto finish;
	}

	rc = k_sem_take(&ipc_settings_data.done, K_FOREVER);

LOG_ERR("uu2 %d", rc);
	if (rc == 0) {
		if (ipc_settings_data.rc < 0) {
			rc = ipc_settings_data.rc;
LOG_ERR("uu3 %d", rc);
		} else {
			*count = ipc_settings_data.rc;
LOG_ERR("uu4 %d", *count);
		}
	}

finish:
	k_sem_give(&ipc_settings_data.busy);
	return rc;
}

int ipc_setting_tree_load(uint16_t index, uint8_t *name, uint8_t *value, uint8_t *value_size)
{
	int rc;
	struct ipc_setting_tree_load_data data;
	struct ipc_setting_tree_load_response_data response_data = {
		.name = name,
		.value = value,
		.value_size = value_size,
	};

#if 0
	uint8_t *name;
	uint8_t *value;
	uint8_t *value_size;
#endif

	data.index = index;

	rc = k_sem_take(&ipc_settings_data.busy, K_FOREVER);

	ipc_settings_data.load_pointer = &response_data;

	rc = ipc_send_message(IPC_OPCODE_SETTINGS_TREE_LOAD, sizeof(data), (uint8_t *)&data);
//	free(data);

//check length?
	if (rc < 0) {
		goto finish;
	}

	rc = k_sem_take(&ipc_settings_data.done, K_FOREVER);

	if (rc == 0) {
		rc = ipc_settings_data.rc;
	}

finish:
#if 0
	if (response_data != NULL) {
		free(response_data);
		response_data = NULL;
	}
#endif

	k_sem_give(&ipc_settings_data.busy);
	return rc;
}
#endif
#endif

static int ipc_settings_register(void)
{
	k_sem_init(&ipc_settings_data.busy, 1, 1);
	k_sem_init(&ipc_settings_data.done, 0, 1);
#if defined(CONFIG_IPC_SETTINGS_CLIENT)
	ipc_settings_data.load_pointer = NULL;
	ipc_settings_data.load_size = 0;
#endif

	ipc_register(&ipc_group_save);
	ipc_register(&ipc_group_load);
	ipc_register(&ipc_group_commit);
#if 0
	ipc_register(&ipc_group_tree_count);
	ipc_register(&ipc_group_tree_load);
#endif
	ipc_register(&ipc_group_boot_load);

	return 0;
}

SYS_INIT(ipc_settings_register, APPLICATION, 0);
```

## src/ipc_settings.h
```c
/*
 * Copyright (c) 2025, Jamie M.
 *
 * All right reserved. This code is NOT apache or FOSS/copyleft licensed.
 */

#include <stdint.h>

int ipc_setting_save(uint8_t *name, uint8_t *value, uint8_t value_size);
int ipc_setting_load(uint8_t *name, uint8_t *value, uint8_t max_value_size);
int ipc_setting_commit(void);
int ipc_setting_tree_count(uint16_t *count);
int ipc_setting_boot_load(uint8_t *key);
```

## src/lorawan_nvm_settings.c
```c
/*
 * Copyright (c) 2022 Intellinium <giuliano.franchetto@intellinium.com>
 * Copyright (c) 2025, Jamie M.
 *
 * SPDX-License-Identifier: Apache-2.0
 */

#include <LoRaMac.h>
#include <zephyr/kernel.h>
#include <zephyr/settings/settings.h>
#include <zephyr/logging/log.h>
#include "lorawan_nvm_settings.h"

LOG_MODULE_REGISTER(lorawan_nvm, CONFIG_LORAWAN_LOG_LEVEL);

#define NVM_SETTING_VALUE_DESCR(_name) \
	static uint8_t setting_value_ ## _name[sizeof(((LoRaMacNvmData_t *)0)->_name)]; \
	static bool setting_loaded_ ## _name

#define NVM_SETTING_DESCR(_flag, _member)				\
	{								\
		.flag = _flag,						\
		.name = STRINGIFY(_member),				\
		.setting_name =						\
			LORAWAN_SETTINGS_BASE "/" STRINGIFY(_member),	\
		.offset = offsetof(LoRaMacNvmData_t, _member),		\
		.size = sizeof(((LoRaMacNvmData_t *)0)->_member),	\
		.data = setting_value_ ## _member,			\
		.loaded = &setting_loaded_ ## _member,			\
	}

NVM_SETTING_VALUE_DESCR(Crypto);
NVM_SETTING_VALUE_DESCR(MacGroup1);
NVM_SETTING_VALUE_DESCR(MacGroup2);
NVM_SETTING_VALUE_DESCR(SecureElement);
NVM_SETTING_VALUE_DESCR(RegionGroup2);

static const struct lorawan_nvm_setting_descr nvm_setting_descriptors[] = {
	NVM_SETTING_DESCR(LORAMAC_NVM_NOTIFY_FLAG_CRYPTO, Crypto),
	NVM_SETTING_DESCR(LORAMAC_NVM_NOTIFY_FLAG_MAC_GROUP1, MacGroup1),
	NVM_SETTING_DESCR(LORAMAC_NVM_NOTIFY_FLAG_MAC_GROUP2, MacGroup2),
	NVM_SETTING_DESCR(LORAMAC_NVM_NOTIFY_FLAG_SECURE_ELEMENT, SecureElement),
	NVM_SETTING_DESCR(LORAMAC_NVM_NOTIFY_FLAG_REGION_GROUP2, RegionGroup2),
};

const uint16_t lorawan_nvm_settings_entries = ARRAY_SIZE(nvm_setting_descriptors);

static void lorawan_nvm_save_settings(uint16_t nvm_notify_flag)
{
	MibRequestConfirm_t mib_req;
	LoRaMacNvmData_t *nvm;

	LOG_DBG("Saving LoRaWAN settings");

	/* Retrieve the actual context */
	mib_req.Type = MIB_NVM_CTXS;

	if (LoRaMacMibGetRequestConfirm(&mib_req) != LORAMAC_STATUS_OK) {
		LOG_ERR("Could not get NVM context");
		return;
	}

	nvm = mib_req.Param.Contexts;

	LOG_DBG("Crypto version: %"PRIu32", DevNonce: %d, JoinNonce: %"PRIu32,
		mib_req.Param.Contexts->Crypto.LrWanVersion.Value,
		mib_req.Param.Contexts->Crypto.DevNonce,
		mib_req.Param.Contexts->Crypto.JoinNonce);

	for (uint32_t i = 0; i < ARRAY_SIZE(nvm_setting_descriptors); i++) {
		const struct lorawan_nvm_setting_descr *descr =
			&nvm_setting_descriptors[i];

		if ((nvm_notify_flag & descr->flag) == descr->flag) {
			int rc;

			LOG_DBG("Saving configuration " LORAWAN_SETTINGS_BASE "/%s", descr->name);
			rc = settings_save_one(descr->setting_name, (char *)nvm + descr->offset,
					       descr->size);

			if (rc != 0) {
				LOG_ERR("Could not save setting " LORAWAN_SETTINGS_BASE "/%s: %d",
					descr->name, rc);
			}
		}
	}
}

void lorawan_nvm_data_mgmt_event(uint16_t flags)
{
	if (flags != LORAMAC_NVM_NOTIFY_FLAG_NONE) {
		lorawan_nvm_save_settings(flags);
	}
}

int lorawan_nvm_data_restore(void)
{
	int err;
	LoRaMacStatus_t status;
	MibRequestConfirm_t mib_req;

	LOG_DBG("Restoring LoRaWAN settings");

	/* Retrieve the actual context */
	mib_req.Type = MIB_NVM_CTXS;

	if (LoRaMacMibGetRequestConfirm(&mib_req) != LORAMAC_STATUS_OK) {
		LOG_ERR("Could not get NVM context");
		return -EINVAL;
	}


	for (uint32_t i = 0; i < ARRAY_SIZE(nvm_setting_descriptors); i++) {
		const struct lorawan_nvm_setting_descr *descr =
			&nvm_setting_descriptors[i];

		if (*descr->loaded == true) {
LOG_ERR("value %s to %p from %p", descr->name, (void *)((char *)mib_req.Param.Contexts + descr->offset), (void *)descr->data);
			memcpy(((char *)mib_req.Param.Contexts + descr->offset), descr->data, descr->size);
LOG_HEXDUMP_ERR(descr->data, descr->size, "data");
		}
	}

	LOG_DBG("Crypto version: %"PRIu32", DevNonce: %d, JoinNonce: %"PRIu32,
		mib_req.Param.Contexts->Crypto.LrWanVersion.Value,
		mib_req.Param.Contexts->Crypto.DevNonce,
		mib_req.Param.Contexts->Crypto.JoinNonce);

	mib_req.Type = MIB_NVM_CTXS;
	status = LoRaMacMibSetRequestConfirm(&mib_req);

	if (status != LORAMAC_STATUS_OK) {
		LOG_ERR("Could not set the NVM context, error %d", status);
		return -EINVAL;
	}

	LOG_DBG("LoRaWAN context restored");

	return 0;
}

int lorawan_nvm_init(void)
{
	return 0;
}

const struct lorawan_nvm_setting_descr *lorawan_get_nvm_settings()
{
	return nvm_setting_descriptors;
}
```

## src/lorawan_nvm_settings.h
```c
/*
 * Copyright (c) 2022 Intellinium <giuliano.franchetto@intellinium.com>
 * Copyright (c) 2025, Jamie M.
 *
 * SPDX-License-Identifier: Apache-2.0
 */

#ifndef APP_LORAWAN_NVM_SETTINGS_H
#define APP_LORAWAN_NVM_SETTINGS_H

#include <stdlib.h>
#include <stdint.h>
#include <stdbool.h>

#define LORAWAN_SETTINGS_BASE "lorawan/nvm"

struct lorawan_nvm_setting_descr {
	const char *name;
	const char *setting_name;
	uint8_t *data;
	size_t size;
	off_t offset;
	uint16_t flag;
	bool *loaded;
};

extern const uint16_t lorawan_nvm_settings_entries;

const struct lorawan_nvm_setting_descr *lorawan_get_nvm_settings();

#endif /* APP_LORAWAN_NVM_SETTINGS_H */
```

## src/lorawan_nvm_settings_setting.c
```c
/*
 * Copyright (c) 2025, Jamie M.
 *
 * All right reserved. This code is NOT apache or FOSS/copyleft licensed.
 */

#include <zephyr/kernel.h>
#include <zephyr/settings/settings.h>
#include <zephyr/logging/log.h>
#include "lorawan_nvm_settings.h"

LOG_MODULE_REGISTER(lorawan_nvm_setting, CONFIG_LORAWAN_LOG_LEVEL);

static int lora_nvm_handle_set(const char *name, size_t len, settings_read_cb read_cb, void *cb_arg)
{
	const char *next;
	size_t name_len;
	int rc;
	const struct lorawan_nvm_setting_descr *descr = lorawan_get_nvm_settings();

	name_len = settings_name_next(name, &next);

	if (!next) {
		for (uint32_t i = 0; i < lorawan_nvm_settings_entries; i++) {
LOG_ERR("names %s vs %s", descr[i].name, name);

			if (strncmp(descr[i].name, name, name_len) == 0) {
				if (len == descr[i].size) {
					rc = read_cb(cb_arg, descr[i].data, len);

					if (rc == len) {
						rc = 0;
						*descr[i].loaded = true;
					}
LOG_ERR("set!");
					return rc;
				} else {
LOG_ERR("size diff %d vs %d", len, descr[i].size);
					return -E2BIG;
				}
			}
		}
	}

	return -ENOENT;
}

SETTINGS_STATIC_HANDLER_DEFINE(lora_nvm, LORAWAN_SETTINGS_BASE, NULL, lora_nvm_handle_set, NULL,
			       NULL);
```
